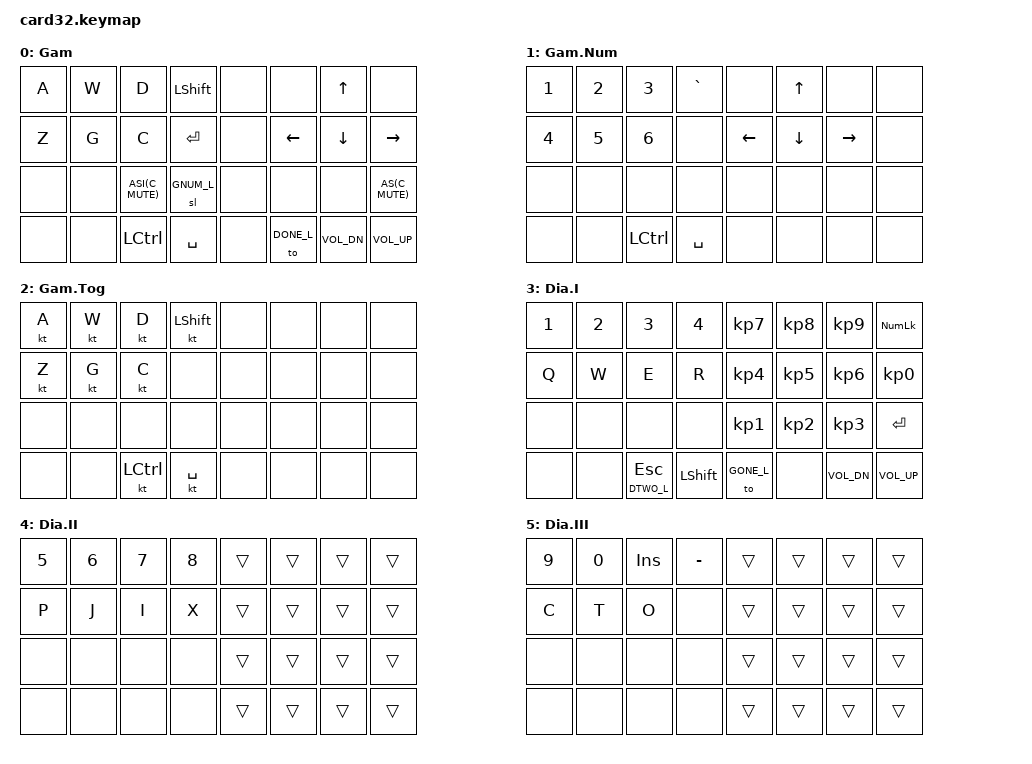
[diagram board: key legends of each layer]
#include <behaviors.dtsi>
#include <dt-bindings/zmk/keys.h>

// Autoshift Macro and Inversion
#define AS(keycode)  &as LS(keycode) keycode
#define ASI(keycode) &as keycode LS(keycode)

#define GONE_L 0
#define GNUM_L 1
#define GTOG_L 2
#define DONE_L 3
#define DTWO_L 4
#define DTHR_L 5

// Using layer taps on thumbs, having quick tap as well helps w/ repeating space/backspace
&lt { quick-tap-ms = <200>; };

/ {
  behaviors {
    as: auto_shift {
      compatible = "zmk,behavior-hold-tap";
      #binding-cells = <2>;
      bindings = <&kp>, <&kp>;
      flavor = "tap-preferred";
      tapping-term-ms = <200>;
      quick-tap-ms = <100>;
    };
    ght: game_hold_tap {
      compatible = "zmk,behavior-hold-tap";
      #binding-cells = <2>;
      bindings = <&kp>, <&kp>;
      flavor = "hold-preferred";
      tapping-term-ms = <150>;
    };
    glt: game_layer_tap {
      compatible = "zmk,behavior-hold-tap";
      #binding-cells = <2>;
      bindings = <&mo>, <&kp>;
      flavor = "hold-preferred";
      tapping-term-ms = <150>;
    };
  };

  keymap {
    compatible = "zmk,keymap";
    gaming_layer {
      display-name = "Gam";
      bindings = <
        &kp A &kp W &kp D       &kp LSHFT    &none &none      &kp UP       &none
        &kp Z &kp G &kp C       &kp RET      &none &kp LEFT   &kp DOWN     &kp RIGHT
        &none &none ASI(C_MUTE) &sl GNUM_L   &none &none      &none        AS(C_MUTE)
        &none &none &kp LCTL    &kp SPACE    &none &to DONE_L &kp C_VOL_DN &kp C_VOL_UP
      >;
    };
    gaming_number_layer {
      display-name = "Gam.Num";
      bindings = <
        &kp N1 &kp N2 &kp N3   &kp GRAVE     &none    &kp UP   &none     &none
        &kp N4 &kp N5 &kp N6   &none         &kp LEFT &kp DOWN &kp RIGHT &none
        &none &none   &none    &none         &none    &none    &none     &none
        &none &none   &kp LCTL &kp SPACE     &none    &none    &none     &none
      >;
    };
    gaming_toggles_layer {
      display-name = "Gam.Tog";
      bindings = <
        &kt A &kt W &kt D    &kt LSHFT    &none &none &none &none
        &kt Z &kt G &kt C    &none        &none &none &none &none
        &none &none &none    &none        &none &none &none &none
        &none &none &kt LCTL &kt SPACE    &none &none &none &none
      >;
    };
    diablo_layer {
      display-name = "Dia.I";
      bindings = <
        &kp N1 &kp N2 &kp N3         &kp N4       &kp KP_N7  &kp KP_N8 &kp KP_N9    &kp KP_NUM
        &kp Q  &kp W  &kp E          &kp R        &kp KP_N4  &kp KP_N5 &kp KP_N6    &kp KP_N0
        &none  &none  &none          &none        &kp KP_N1  &kp KP_N2 &kp KP_N3    &kp RET
        &none &none   &lt DTWO_L ESC &kp LSHFT    &to GONE_L &none     &kp C_VOL_DN &kp C_VOL_UP
      >;
    };
    diablo_two_layer {
      display-name = "Dia.II";
      bindings = <
        &kp N5 &kp N6 &kp N7 &kp N8    &trans &trans &trans &trans
        &kp P  &kp J  &kp I  &kp X     &trans &trans &trans &trans
        &none  &none  &none  &none     &trans &trans &trans &trans
        &none  &none  &none  &none     &trans &trans &trans &trans
      >;
    };
    diablo_three_layer {
      display-name = "Dia.III";
      bindings = <
        &kp N9 &kp N0 &kp INS &kp MINUS    &trans &trans &trans &trans
        &kp C  &kp T  &kp O   &none        &trans &trans &trans &trans
        &none  &none  &none   &none        &trans &trans &trans &trans
        &none  &none  &none   &none        &trans &trans &trans &trans
      >;
    };
  };

  /*
   *  0  1  2  3     4  5  6  7
   *  8  9 10 11    12 13 14 15
   * 16 17 18 19    20 21 22 23
   * 24 25 26 27    28 29 30 31
   */

  combos {
    compatible = "zmk,combos";
    combo_bootloader { timeout-ms = <50>; key-positions = <0 7 24 31>; bindings = <&bootloader>; };

    combo_esc   { timeout-ms = <50>; key-positions = <2 3>;   bindings = <&kp ESC>;    layers = <GONE_L>; };
    combo_tab   { timeout-ms = <50>; key-positions = <3 27>;  bindings = <&kp TAB>;    layers = <GONE_L>; };
    combo_caps  { timeout-ms = <50>; key-positions = <2 3 27>;bindings = <&kp CAPS>;   layers = <GONE_L>; };
    combo_q     { timeout-ms = <50>; key-positions = <0 27>;  bindings = <&kp Q>;      layers = <GONE_L>; };
    combo_e     { timeout-ms = <50>; key-positions = <2 27>;  bindings = <&kp E>;      layers = <GONE_L>; };
    combo_r     { timeout-ms = <50>; key-positions = <2 26>;  bindings = <&kp R>;      layers = <GONE_L>; };
    combo_s     { timeout-ms = <50>; key-positions = <1 27>;  bindings = <&kp S>;      layers = <GONE_L>; slow-release; };
    combo_f     { timeout-ms = <50>; key-positions = <0 26>;  bindings = <&kp F>;      layers = <GONE_L>; };
    combo_x     { timeout-ms = <50>; key-positions = <0 2 26>;bindings = <&kp X>;      layers = <GONE_L>; };
    combo_b     { timeout-ms = <50>; key-positions = <0 2 27>;bindings = <&kp B>;      layers = <GONE_L>; };
    combo_v     { timeout-ms = <50>; key-positions = <0 2>;   bindings = <&kp V>;      layers = <GONE_L>; };
    combo_la    { timeout-ms = <50>; key-positions = <19 27>; bindings = <&kp LALT>;   layers = <GONE_L>; };
    combo_lt_num{ timeout-ms = <50>; key-positions = <18 26>; bindings = <&mo GNUM_L>; layers = <GONE_L>; };
    combo_tg_q  { timeout-ms = <50>; key-positions = <0 27>;  bindings = <&kt Q>;      layers = <GONE_L>; };
    combo_tg_e  { timeout-ms = <50>; key-positions = <2 27>;  bindings = <&kt E>;      layers = <GONE_L>; };
    combo_tg_r  { timeout-ms = <50>; key-positions = <2 26>;  bindings = <&kt R>;      layers = <GONE_L>; };
    combo_tg_s  { timeout-ms = <50>; key-positions = <1 27>;  bindings = <&kt S>;      layers = <GONE_L>; };
    combo_tg_f  { timeout-ms = <50>; key-positions = <0 26>;  bindings = <&kt F>;      layers = <GONE_L>; };
    combo_tg_x  { timeout-ms = <50>; key-positions = <0 2 26>;bindings = <&kt X>;      layers = <GONE_L>; };
    combo_tg_c  { timeout-ms = <50>; key-positions = <0 2 27>;bindings = <&kt C>;      layers = <GONE_L>; };
    combo_tg_v  { timeout-ms = <50>; key-positions = <0 2>;   bindings = <&kt V>;      layers = <GONE_L>; };
    combo_tg_la { timeout-ms = <50>; key-positions = <19 27>; bindings = <&kt LALT>;   layers = <GONE_L>; };
    combo_sl_tg { timeout-ms = <50>; key-positions = <8 10>;  bindings = <&sl GTOG_L>; layers = <GONE_L>; };
    combo_d2_lc     { timeout-ms = <50>; key-positions = <18 26>; bindings = <&kp LCTRL>;     layers = <DONE_L>; };
    combo_d2_grave  { timeout-ms = <50>; key-positions = <2 3>;   bindings = <&kp GRAVE>;     layers = <DONE_L>; };
    combo_d2_lt_3_z { timeout-ms = <50>; key-positions = <19 27>; bindings = <&glt DTHR_L Z>; layers = <DONE_L>; };
  };
};
// vim: ft=c
